# BL616/BL618 register map
Vendor: Bouffalo Lab; File version: 1.0
Registers are 32-bit, read-write, reset 0x0 unless marked. A register's access mark holds for its fields unless they carry their own. Offsets are from the block's base; [hi:lo] are bit positions; {n}, {i} and the like mark numbered series; 'fields as' and 'values as' point back to an identical list.

## UART[{n}] — Universal Asynchronous Receiver Transmitter
Base 0x2000A000; array of 2, step 0x100
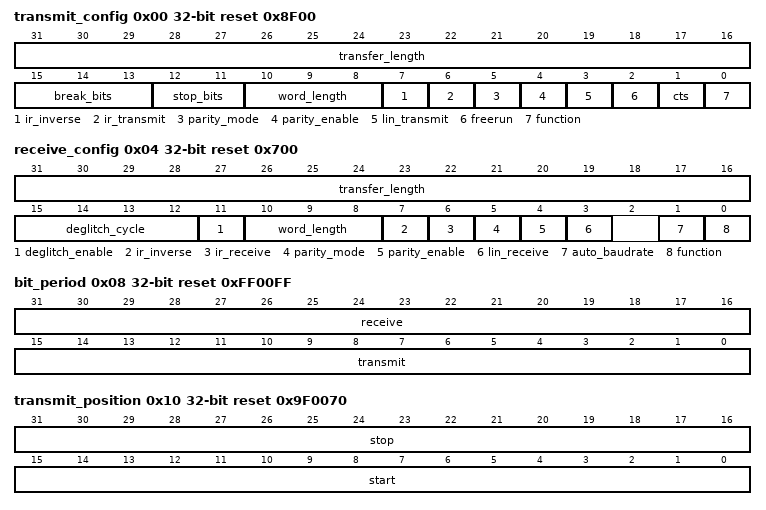
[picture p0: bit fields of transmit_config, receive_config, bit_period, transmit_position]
0x00 transmit_config reset 0x8F00 — Transmit configuration register
  [31:16] transfer_length — Length of words per UART transmit transfer . This field is ignored when `freerun` mode is enabled.
  [15:13] break_bits — Number of break bits for LIN protocol
  [12:11] stop_bits — Number of stop bits
    0=zero_p_five (0.5 stop bits); 1=one (1 stop bit); 2=one_p_five (1.5 stop bits); 3=two (2 stop bits)
  [10:8] word_length — Bit count for each transmit data word
    4=five (Each word includes 5 bits); 5=six (Each word includes 6 bits); 6=seven (Each word includes 7 bits); 7=eight (Each word includes 8 bits)
  [7] ir_inverse — Inverse transmit signal output in IR mode
    1=Inverse transmit input in IR mode; 0=no_inverse (Don't inverse transmit input in IR mode)
  [6] ir_transmit — Enable IR transmit mode
    1=Enable IR transmit mode; 0=Disable IR transmit mode
  [5] parity_mode — Select transmit parity mode if enabled
    1=odd (Odd parity if `parity_enable` is set); 0=Even parity if `parity_enable` is set
  [4] parity_enable — Enable transmit parity check
    1=Enable transmit parity check; 0=Disable transmit parity check
  [3] lin_transmit — Local Interconnect Network protocol enable
    1=Enable Local Interconnect Network protocol; 0=Disable Local Interconnect Network protocol
  [2] freerun — Enable freerun mode
    1=Enable freerun mode; 0=Disable freerun mode
  [1] cts — Enable Clear-to-Send flow control signal
    1=Enable Clear-to-Send flow control signal; 0=Disable Clear-to-Send flow control signal
  [0] function — Enable transmit function
    1=Enable UART receive function signal; 0=Disable UART receive function signal
0x04 receive_config reset 0x700 — Receive configuration register
  [31:16] transfer_length — Length of words per UART receive transfer
  [15:12] deglitch_cycle — De-glitch function cycle count
  [11] deglitch_enable — Enable receive de-glitch function
    1=Enable de-glitch function upon receive; 0=Disable de-glitch function upon receive
  [10:8] word_length — Bit count for each receive data word
    values as transmit_config.word_length
  [7] ir_inverse — Inverse receive signal output in IR mode
    1=Inverse receive input in IR mode; 0=no_inverse (Don't inverse receive input in IR mode)
  [6] ir_receive — Enable IR receive mode
    1=Enable IR receive mode; 0=Disable IR receive mode
  [5] parity_mode — Select receive parity mode if enabled
    values as transmit_config.parity_mode
  [4] parity_enable — Enable receive parity check
    1=Enable receive parity check; 0=Disable receive parity check
  [3] lin_receive — Local Interconnect Network protocol enable
    values as transmit_config.lin_transmit
  [1] auto_baudrate — Enable receive auto baudrate detection
    1=Enable auto baudrate upon receive; 0=Disable auto baudrate upon receive
  [0] function — Enable receive function
    values as transmit_config.function
0x08 bit_period reset 0xFF00FF — Bit period control register
  [31:16] receive — Period of each receive bit . Add 1 to this value and divide by clock to get receive baudrate.
  [15:0] transmit — Period of each transmit bit . Add 1 to this value and divide by clock to get transmit baudrate.
0x0C data_config — Data configuration register
  [0] bit_order — Enable bit inverse in each data word
    1=inverse (Each byte is sent out MSB-first); 0=no_inverse (Each byte is sent out LSB-first)
0x10 transmit_position reset 0x9F0070 — IR-mode transmit position control
  [31:16] stop — Stop position of transmit IR pulse
  [15:0] start — Start position of transmit IR pulse
0x14 receive_position reset 0x6F — IR-mode receive position control
  [15:0] start — Start position of received pulse recovered from IR signal
0x18 receive_timeout reset 0xF — Receive Time-Out interrupt control
  [7:0] value — Timeout interrupt triggering value by bits received
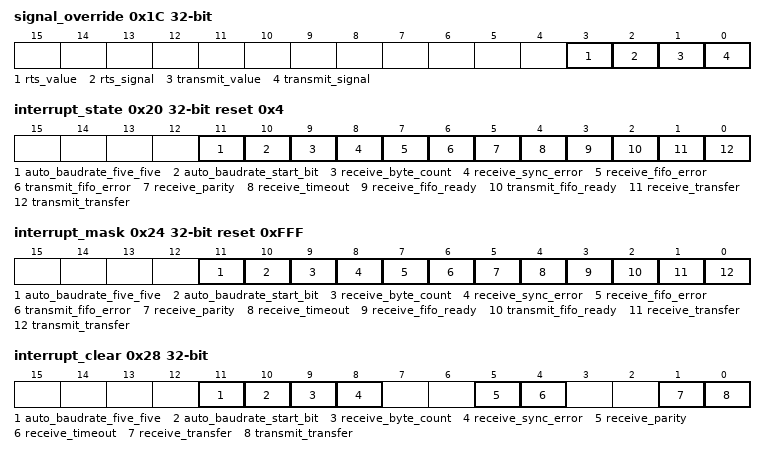
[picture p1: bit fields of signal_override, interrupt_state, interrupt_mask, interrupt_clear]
0x1C signal_override — Manual override of flow control signal
  [3] rts_value — Value to override Request-to-Send signal if override is enabled
    1=high (Assert this signal); 0=low (Deassert this signal)
  [2] rts_signal — Enable manual override of Request-to-Send flow control signal
    1=Enable manual override of this signal; 0=Disable manual override of this signal
  [1] transmit_value — Value to override transmit signal if override is enabled
    1=high (Assert this signal); 0=low (Deassert this signal)
  [0] transmit_signal — Enable manual override of transmit signal
    values as rts_signal
0x20 interrupt_state ro reset 0x4
  [all] fields
    1=has_interrupt; 0=No interrupt occurred
  [11] auto_baudrate_five_five — Receive auto baudrate detection finished using 0x55 occurred
  [10] auto_baudrate_start_bit — Receive auto baudrate detection finished using start bit occurred
  [9] receive_byte_count — Receive byte count reached occurred
  [8] receive_sync_error — Receive LIN mode synchronization field error occurred
  [7] receive_fifo_error — Receive FIFO overflow or underflow occurred
  [6] transmit_fifo_error — Transmit FIFO overflow or underflow occurred
  [5] receive_parity — Receive parity check failure occurred
  [4] receive_timeout — Receive timed-out interrupt occurred
  [3] receive_fifo_ready — Receive FIFO ready signal raised
  [2] transmit_fifo_ready — Transmit FIFO ready signal raised
  [1] receive_transfer — Receive transfer finish signal raised
  [0] transmit_transfer — Transmit transfer finish signal raised
0x24 interrupt_mask reset 0xFFF
  [all] fields
    1=Mask interrupt; 0=Unmask interrupt
  [11] auto_baudrate_five_five — Receive auto baudrate detection finished using 0x55 occurred
  [10] auto_baudrate_start_bit — Receive auto baudrate detection finished using start bit interrupt mask
  [9] receive_byte_count — Receive byte count reached interrupt mask
  [8] receive_sync_error — Receive LIN mode synchronization field error interrupt mask
  [7] receive_fifo_error — Receive FIFO overflow or underflow interrupt mask
  [6] transmit_fifo_error — Transmit FIFO overflow or underflow interrupt mask
  [5] receive_parity — Receive parity check failure interrupt mask
  [4] receive_timeout — Receive timed-out interrupt mask
  [3] receive_fifo_ready — Receive FIFO ready signal interrupt mask
  [2] transmit_fifo_ready — Transmit FIFO ready signal interrupt mask
  [1] receive_transfer — Receive transfer finish signal interrupt mask
  [0] transmit_transfer — Transmit transfer finish signal interrupt mask
0x28 interrupt_clear wo — Clear interrupt register
  [all] fields
    1=clear (Write 1 to clear interrupt state)
  [11] auto_baudrate_five_five — Write 1 to clear receive auto baudrate detection finished using 0x55
  [10] auto_baudrate_start_bit — Write 1 to clear receive auto baudrate detection finished using start bit
  [9] receive_byte_count — Write 1 to clear receive byte count reached
  [8] receive_sync_error — Write 1 to clear receive LIN mode synchronization field error
  [5] receive_parity — Write 1 to clear receive parity check failure
  [4] receive_timeout — Write 1 to clear receive timed-out
  [1] receive_transfer — Write 1 to clear receive transfer finish signal
  [0] transmit_transfer — Write 1 to clear transmit transfer finish signal
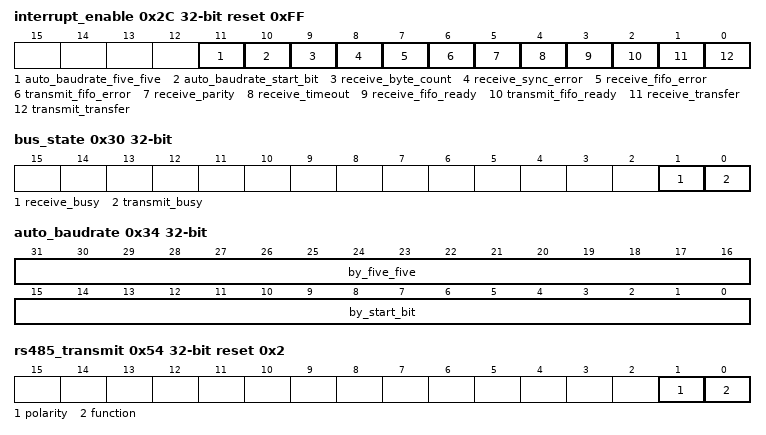
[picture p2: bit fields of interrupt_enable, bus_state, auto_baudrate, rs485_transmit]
0x2C interrupt_enable reset 0xFF
  [all] fields
    1=Enable interrupt; 0=Disable interrupt
  [11] auto_baudrate_five_five — Receive auto baudrate detection finished using 0x55 interrupt enable
  [10] auto_baudrate_start_bit — Receive auto baudrate detection finished using start bit interrupt enable
  [9] receive_byte_count — Receive byte count reached interrupt enable
  [8] receive_sync_error — Receive LIN mode synchronization field error interrupt enable
  [7] receive_fifo_error — Receive FIFO overflow or underflow interrupt enable
  [6] transmit_fifo_error — Transmit FIFO overflow or underflow interrupt enable
  [5] receive_parity — Receive parity check failure interrupt enable
  [4] receive_timeout — Receive timed-out interrupt enable
  [3] receive_fifo_ready — Receive FIFO ready signal interrupt enable
  [2] transmit_fifo_ready — Transmit FIFO ready signal interrupt enable
  [1] receive_transfer — Receive transfer signal interrupt enable
  [0] transmit_transfer — Transmit transfer signal interrupt enable
0x30 bus_state ro
  [1] receive_busy — Indicates that UART receive bus is busy
    1=busy (Bus is busy); 0=idle (Bus is not busy)
  [0] transmit_busy — Indicates that UART transmit bus is busy
    1=busy (Bus is busy); 0=idle (Bus is not busy)
0x34 auto_baudrate ro — Auto baudrate detection register
  [31:16] by_five_five — Bit period of auto baudrate detection using codeword 0x55
  [15:0] by_start_bit — Bit period of auto baudrate detection using start bit
0x48 pulse_tolerance reset 0x3 — Pulse width tolerance for auto baudrate
  [7:0] by_five_five — Pulse width tolerance of auto baudrate detection using codeword 0x55
0x54 rs485_transmit reset 0x2 — RS-485 mode transmit configuration
  [1] polarity — RS-485 pin polarity of Driver Enable (DE) pin
    1=active_high (Driver Enable (DE) pin is active high); 0=active_low (Driver Enable (DE) pin is active low)
  [0] function — RS-485 transceiver mode enable
    1=Enable RS-485 transceiver mode . The peripheral is connected to RS-485 transceiver, and RTS signal output becomes Driver Enable (DE) signal.; 0=Disable RS-485 transceiver mode . The peripheral operates as normal UART.
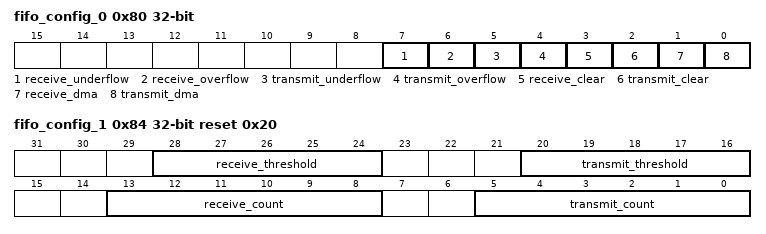
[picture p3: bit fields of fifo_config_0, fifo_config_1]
0x80 fifo_config_0 — FIFO configuration register 0
  [7] receive_underflow ro — Receive FIFO underflow flag . Can be cleared using `receive_clear`.
    0=not_underflow (No FIFO buffer underflow); 1=underflow (Has FIFO buffer underflow)
  [6] receive_overflow ro — Receive FIFO overflow flag . Can be cleared using `receive_clear`.
    0=not_overflow (No FIFO buffer overflow); 1=overflow (Has FIFO buffer overflow)
  [5] transmit_underflow ro — Transmit FIFO underflow flag . Can be cleared using `transmit_clear`.
    values as receive_underflow
  [4] transmit_overflow ro — Transmit FIFO overflow flag . Can be cleared using `transmit_clear`.
    values as receive_overflow
  [3] receive_clear wo — Clears receive FIFO overflow and underflow flags
    1=clear (Write 1 to clear fifo flags)
  [2] transmit_clear wo — Clears transmit FIFO overflow and underflow flags
    1=clear (Write 1 to clear fifo flags)
  [1] receive_dma — Enable signal of receive DMA interface
    1=Enable DMA interface; 0=Disable DMA interface
  [0] transmit_dma — Enable signal of transmit DMA interface
    1=Enable DMA interface; 0=Disable DMA interface
0x84 fifo_config_1 reset 0x20 — FIFO configuration register 1
  [28:24] receive_threshold — Receive FIFO threshold . DMA request will not be asserted if `receive_available` is less than this value
  [20:16] transmit_threshold — Transmit FIFO threshold . DMA request will not be asserted if `transmit_available` is less than this value
  [13:8] receive_count ro — Count of available data in receive FIFO
  [5:0] transmit_count ro — Count of available data in transmit FIFO
0x88 data_write wo — FIFO write data register
  [7:0] value — Write data to FIFO
0x8C data_read ro — FIFO read data register
  [7:0] value — Read data from FIFO
